# DSP_ICFG register map
Vendor: Texas Instruments
Peripheral module from a debugger description file (folder xwr16xx).
Registers are 32-bit, read-write, no defined reset value unless marked. A register's access mark holds for its fields unless they carry their own. Offsets are as the file gives them; lines under a group give offsets from that group; [hi:lo] are bit positions; {n}, {i} and the like mark numbered series; 'fields as' and 'values as' point back to an identical list; <NAME> marks a mode.

## DSP_ICFG
{0x800000+4i} EVTFLAG{i} (i=0..3) — Event flags
  [31:0] EF — Bitfield description is not available - (RO )
{0x800020+4i} EVTSET{i} (i=0..3) — Event set command register
  [31:0] ES — Event set command - (WO )
{0x800040+4i} EVTCLR{i} (i=0..3) — Event clear command register
  [31:0] EC — Event clear command - (WO )
{0x800080+4i} EVTMASK{i} (i=0..3) — Event mask register
  [31:0] EM — Event mask - (RW )
{0x8000A0+4i} MEVTFLAG{i} (i=0..3) — Masked event flags
  [31:0] MEVTFLAG — Masked event flags - (RO )
{0x8000C0+4i} EXPMASK{i} (i=0..3) — Exception mask register
  [31:0] XM — Exception mask - (RW )
{0x8000E0+4i} MEXPFLAG{i} (i=0..3) — Masked exception flags
  [31:0] MEXPFLAG — Masked exception flags - (RO )
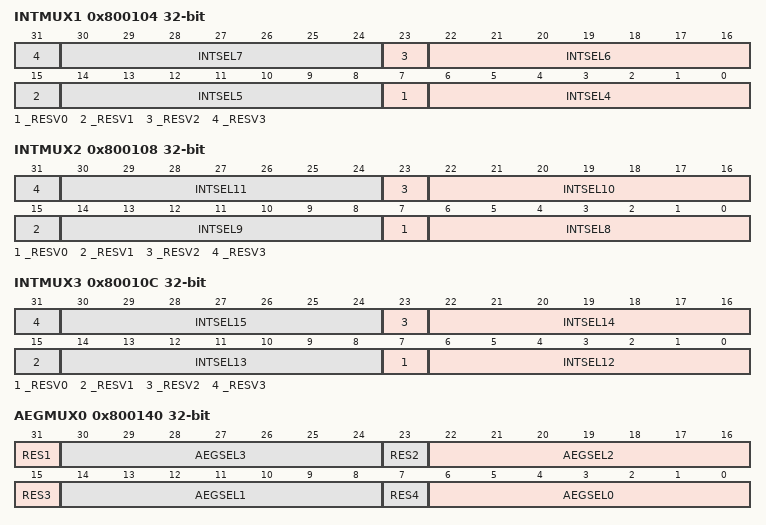
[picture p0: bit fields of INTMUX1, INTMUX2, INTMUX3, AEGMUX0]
0x800104 INTMUX1 — Interrupt Mux Register
  [8n+7] _RESV{n} (n=0..3) — Always read as 0. Writes have no affect. - (RW )
  [8n-26:8n-32] INTSEL{n} (n=4..7) — Interrupt selector {n} - (RW )
0x800108 INTMUX2 — Interrupt Mux Register
  [8n+7] _RESV{n} (n=0..3) — Always read as 0. Writes have no affect. - (RW )
  [8n-58:8n-64] INTSEL{n} (n=8..11) — Interrupt selector {n} - (RW )
0x80010C INTMUX3 — Interrupt Mux Register
  [8n+7] _RESV{n} (n=0..3) — Always read as 0. Writes have no affect. - (RW )
  [8n-90:8n-96] INTSEL{n} (n=12..15) — Interrupt selector {n} - (RW )
0x800140 AEGMUX0 access per field — AEG Event Mux Register
  [39-8n] RES{n} ro (n=1..4) — RESERVE FIELD
  [8n+6:8n] AEGSEL{n} rw (n=0..3) — AEG event selector {n} - (RW )
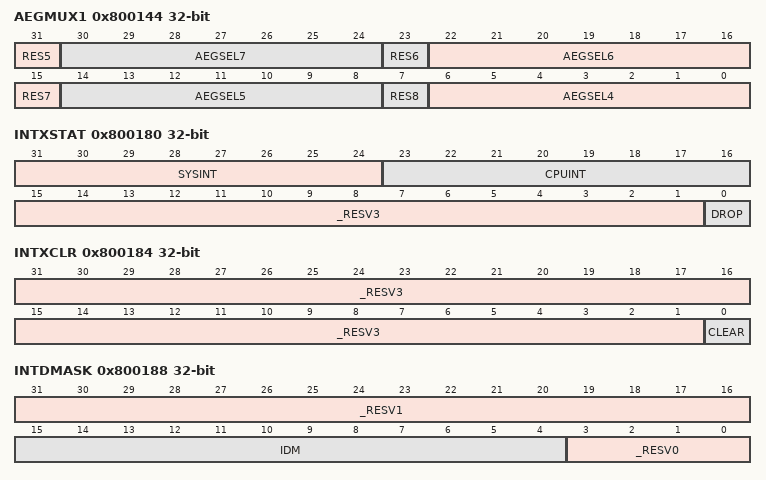
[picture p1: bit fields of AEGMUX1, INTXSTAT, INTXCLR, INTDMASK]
0x800144 AEGMUX1 access per field — AEG Event Mux Register
  [71-8n] RES{n} ro (n=5..8) — RESERVE FIELD
  [8n-26:8n-32] AEGSEL{n} rw (n=4..7) — AEG event selector {n} - (RW )
0x800180 INTXSTAT — Interrupt Exception Status Register
  [31:24] SYSINT — System event number - (RO )
  [23:16] CPUINT — CPU interrupt number - (RO )
  [15:1] _RESV3 — Always read as 0. Writes have no affect. - (RW )
  [0] DROP — Dropped event flag - (RO )
0x800184 INTXCLR — Interrupt Exception Clear Register
  [31:1] _RESV3 — Always read as 0. Writes have no affect. - (RW )
  [0] CLEAR — Clear interrupt exception status - (WO )
0x800188 INTDMASK — Dropped Interrupt Mask Register
  [31:16] _RESV1 — Always read as 0. Writes have no affect. - (RW )
  [15:4] IDM — Interrupt drop mask - (RW )
  [3:0] _RESV0 — Always read as 0. Writes have no affect. - (RW )
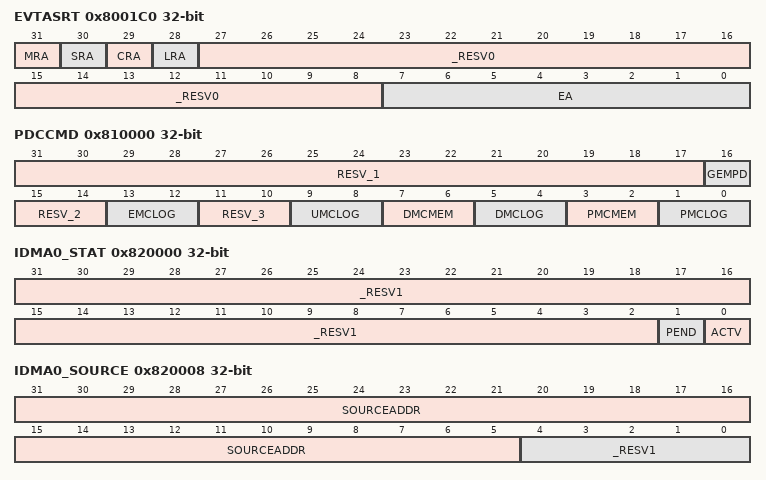
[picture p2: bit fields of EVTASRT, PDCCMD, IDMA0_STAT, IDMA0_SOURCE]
0x8001C0 EVTASRT — Event Assert Register
  [31] MRA — Maximal Reset Request Assert - (WO )
  [30] SRA — System Reset Request Assert - (WO )
  [29] CRA — Chip Reset Request Assert - (WO )
  [28] LRA — Local Reset Request Assert - (WO )
  [27:8] _RESV0 — Always read as 0. Writes have no affect. - (RW )
  [7:0] EA — Event Assert - (WO )
0x810000 PDCCMD — Register description is not available
  [31:17] RESV_1 — Always read as 0. Writes have no affect. - (RW )
  [16] GEMPD — Enable power-down during IDLE - (RW )
  [15:14] RESV_2 — Always read as 0. Writes have no affect. - (RW )
  [13:12] EMCLOG — EMC SRAM Sleep Mode - (RW )
  [11:10] RESV_3 — Always read as 0. Writes have no affect. - (RW )
  [9:8] UMCLOG — UMC SRAM Sleep Mode - (RW )
  [7:6] DMCMEM — DMC Logic Clock Gating - (RW )
  [5:4] DMCLOG — DMC SRAM Sleep Mode - (RW )
  [3:2] PMCMEM — PMC Logic Clock Gating - (RW )
  [1:0] PMCLOG — PMC SRAM Sleep Mode - (RW )
0x812000 MM_REVID — Register description is not available
  [31:0] MM_REVID — Bitfield description is not available - (RW )
0x820000 IDMA0_STAT — IDMA Channel 0 Status
  [31:2] _RESV1 — Always read as 0. Writes have no affect. - (RW )
  [1] PEND — Command pending - (RO )
  [0] ACTV — Command active - (RO )
0x820004 IDMA0_MASK — IDMA Channel 0 Register Mask
  [31:0] MASK — Register mask - (RW )
0x820008 IDMA0_SOURCE — IDMA Channel 0 Source Address
  [31:5] SOURCEADDR — Source address - (RW )
  [4:0] _RESV1 — Always read as 0. Writes have no affect. - (RW )
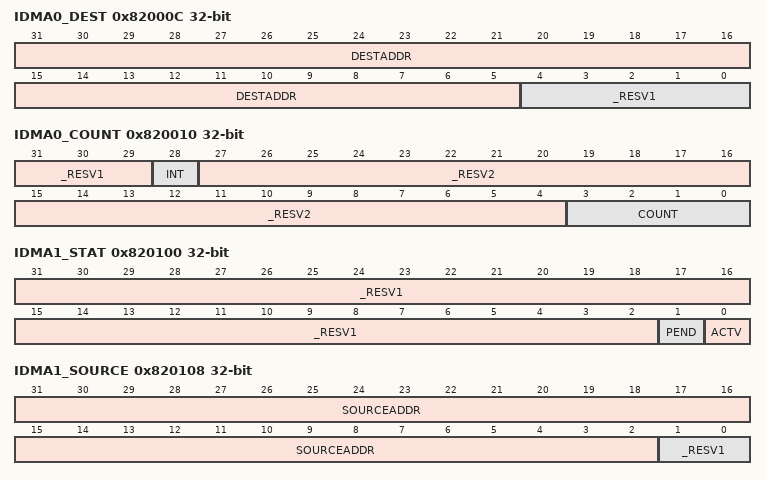
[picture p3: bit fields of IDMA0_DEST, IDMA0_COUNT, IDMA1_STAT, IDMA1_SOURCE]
0x82000C IDMA0_DEST — IDMA Channel 0 Destination Address
  [31:5] DESTADDR — Destination address - (RW )
  [4:0] _RESV1 — Always read as 0. Writes have no affect. - (RW )
0x820010 IDMA0_COUNT — IDMA Channel 0 Count
  [31:29] _RESV1 — Always read as 0. Writes have no affect. - (RW )
  [28] INT — Interrupt enable - (RW )
  [27:4] _RESV2 — Always read as 0. Writes have no affect. - (RW )
  [3:0] COUNT — Transfer frame count - (RW )
0x820100 IDMA1_STAT — Register description is not available
  fields as IDMA0_STAT
0x820108 IDMA1_SOURCE — Register description is not available
  [31:2] SOURCEADDR — Source address - (RW )
  [1:0] _RESV1 — Always read as 0. Writes have no affect. - (RW )
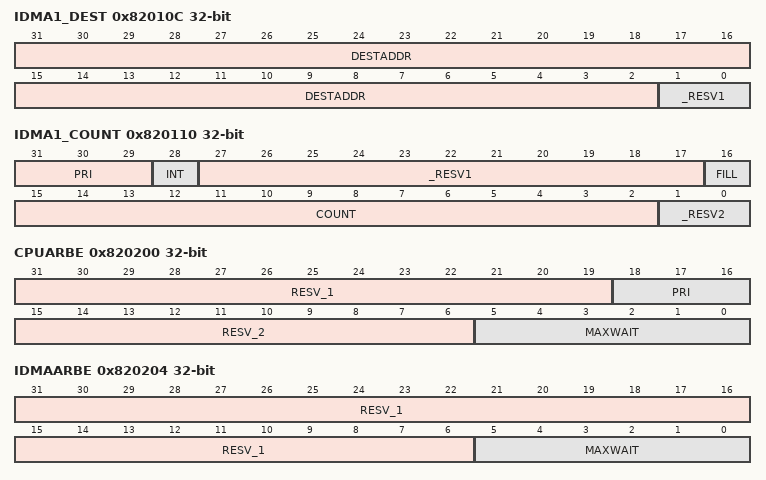
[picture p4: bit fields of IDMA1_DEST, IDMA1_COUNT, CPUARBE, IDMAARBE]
0x82010C IDMA1_DEST — Register description is not available
  [31:2] DESTADDR — Destination address - (RW )
  [1:0] _RESV1 — Always read as 0. Writes have no affect. - (RW )
0x820110 IDMA1_COUNT — Register description is not available
  [31:29] PRI — Priority - (RW )
  [28] INT — Interrupt enable - (RW )
  [27:17] _RESV1 — Always read as 0. Writes have no affect. - (RW )
  [16] FILL — Fill/Copy Mode Select - (RW )
  [15:2] COUNT — Transfer word count - (RW )
  [1:0] _RESV2 — Always read as 0. Writes have no affect. - (RW )
0x820200 CPUARBE — Register description is not available
  [31:19] RESV_1 — Always read as 0. Writes have no affect. - (RW )
  [18:16] PRI — Priority - (RW )
  [15:6] RESV_2 — Always read as 0. Writes have no affect. - (RW )
  [5:0] MAXWAIT — Max wait count - (RW )
0x820204 IDMAARBE — Register description is not available
  [31:6] RESV_1 — Always read as 0. Writes have no affect. - (RW )
  [5:0] MAXWAIT — Max wait count - (RW )
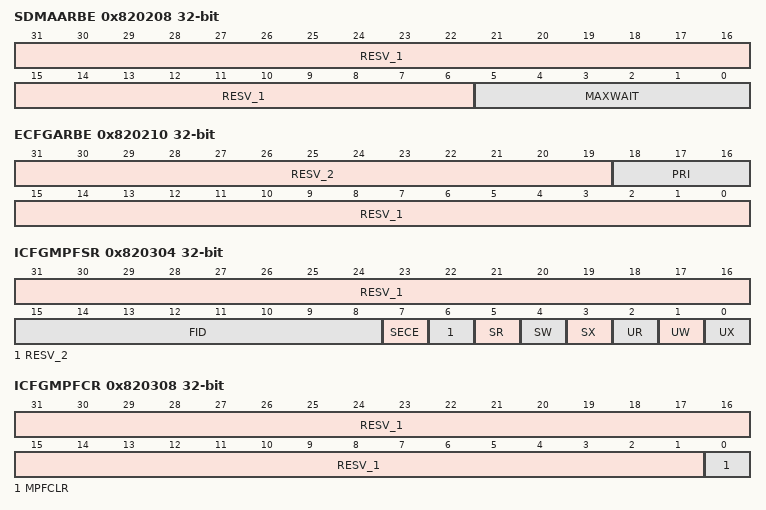
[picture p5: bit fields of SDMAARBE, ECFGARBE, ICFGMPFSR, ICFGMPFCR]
0x820208 SDMAARBE — Register description is not available
  fields as IDMAARBE
0x820210 ECFGARBE — Register description is not available
  [31:19] RESV_2 — Always read as 0. Writes have no affect. - (RW )
  [18:16] PRI — Priority - (RW )
  [15:0] RESV_1 — Always read as 0. Writes have no affect. - (RW )
0x820300 ICFGMPFAR — Register description is not available
  [31:0] ADDR — Bitfield description is not available - (RO )
0x820304 ICFGMPFSR — Register description is not available
  [31:16] RESV_1 — Always read as 0. Writes have no affect. - (RW )
  [15:8] FID — PrivID of faulting requestor - (RO )
  [7] SECE — Security Error - (RO )
  [6] RESV_2 — Always read as 0. Writes have no affect. - (RW )
  [5] SR — Fault due to Supervisor Read - (RO )
  [4] SW — Fault due to Supervisor Write - (RO )
  [3] SX — Fault due to Supervisor Execute - (RO )
  [2] UR — Fault due to User Read - (RO )
  [1] UW — Fault due to User Write - (RO )
  [0] UX — Fault due to User Execute - (RO )
0x820308 ICFGMPFCR — Register description is not available
  [31:1] RESV_1 — Always read as 0. Writes have no affect. - (RW )
  [0] MPFCLR — Bitfield description is not available - (WO )
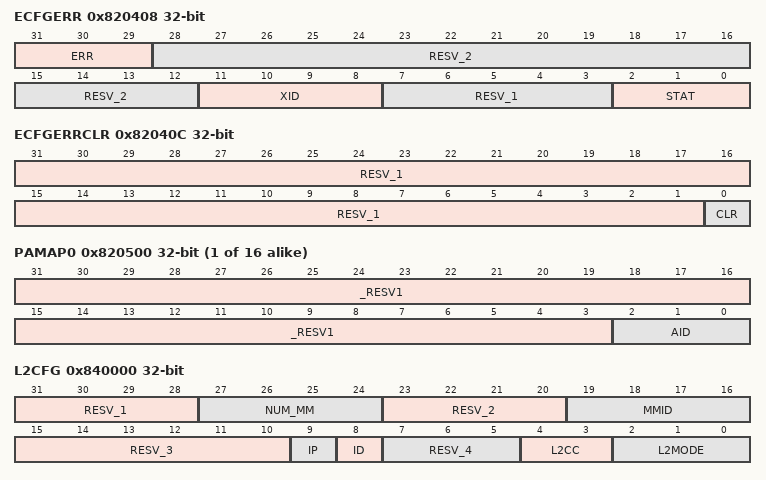
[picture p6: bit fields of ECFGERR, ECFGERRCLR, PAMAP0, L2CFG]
0x820408 ECFGERR — Register description is not available
  [31:29] ERR — Error - (RO )
  [28:12] RESV_2 — Always read as 0. Writes have no affect. - (RW )
  [11:8] XID — XID - (RO )
  [7:3] RESV_1 — Always read as 0. Writes have no affect. - (RW )
  [2:0] STAT — Status - (RO )
0x82040C ECFGERRCLR — Register description is not available
  [31:1] RESV_1 — Always read as 0. Writes have no affect. - (RW )
  [0] CLR — Error clear - (RO )
{0x820500+4i} PAMAP{i} (i=0..15) — PAMAP register
  [31:3] _RESV1 — Always read as 0. Writes have no affect. - (RW )
  [2:0] AID — AID - (RW )
0x840000 L2CFG — Register description is not available
  [31:28] RESV_1 — Always read as 0. Writes have no affect. - (RW )
  [27:24] NUM_MM — Bitfield description is not available - (RO )
  [23:20] RESV_2 — Always read as 0. Writes have no affect. - (RW )
  [19:16] MMID — Bitfield description is not available - (RO )
  [15:10] RESV_3 — Always read as 0. Writes have no affect. - (RW )
  [9] IP — Bitfield description is not available - (RW )
  [8] ID — Bitfield description is not available - (RW )
  [7:5] RESV_4 — Always read as 0. Writes have no affect. - (RW )
  [4:3] L2CC — Bitfield description is not available - (RW )
  [2:0] L2MODE — Bitfield description is not available - (RW )
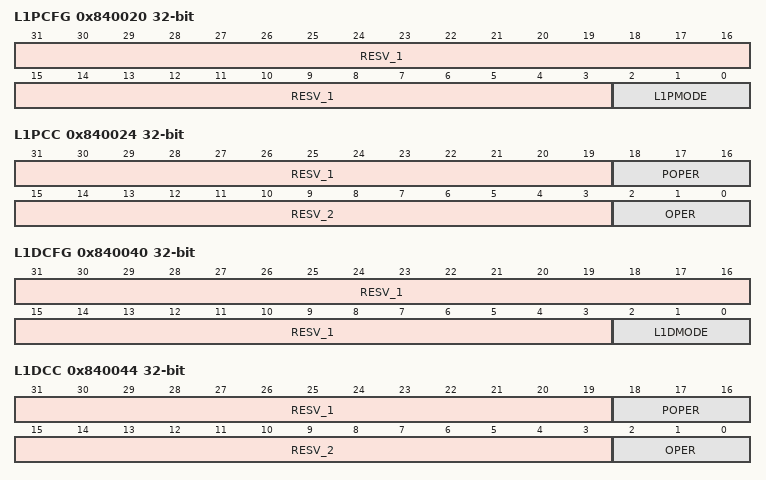
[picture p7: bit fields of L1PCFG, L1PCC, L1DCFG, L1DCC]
0x840020 L1PCFG — Register description is not available
  [31:3] RESV_1 — Always read as 0. Writes have no affect. - (RW )
  [2:0] L1PMODE — Bitfield description is not available - (RW )
0x840024 L1PCC — Register description is not available
  [31:19] RESV_1 — Always read as 0. Writes have no affect. - (RW )
  [18:16] POPER — Bitfield description is not available - (RO )
  [15:3] RESV_2 — Always read as 0. Writes have no affect. - (RW )
  [2:0] OPER — Bitfield description is not available - (RW )
0x840040 L1DCFG — Register description is not available
  [31:3] RESV_1 — Always read as 0. Writes have no affect. - (RW )
  [2:0] L1DMODE — Bitfield description is not available - (RW )
0x840044 L1DCC — Register description is not available
  fields as L1PCC
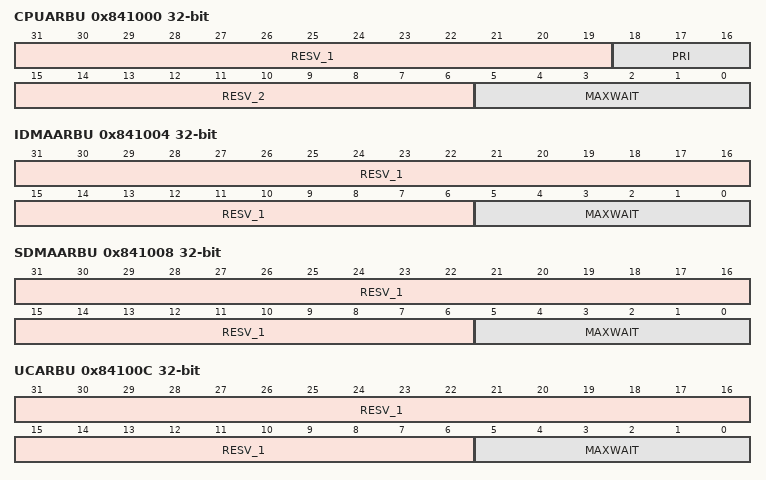
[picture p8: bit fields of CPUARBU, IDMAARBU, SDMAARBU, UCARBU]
0x841000 CPUARBU — Register description is not available
  fields as CPUARBE
0x841004 IDMAARBU — Register description is not available
  fields as IDMAARBE
0x841008 SDMAARBU — Register description is not available
  fields as IDMAARBE
0x84100C UCARBU — Register description is not available
  fields as IDMAARBE
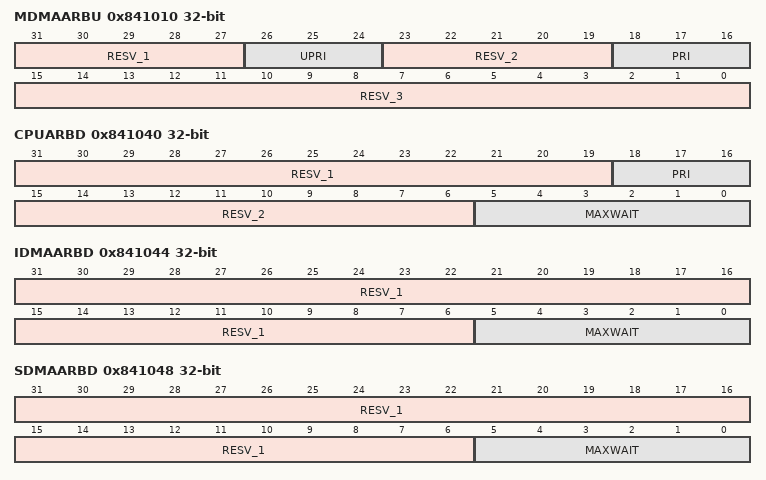
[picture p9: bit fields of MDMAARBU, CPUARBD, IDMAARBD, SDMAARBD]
0x841010 MDMAARBU — Register description is not available
  [31:27] RESV_1 — Always read as 0. Writes have no affect. - (RW )
  [26:24] UPRI — Elevated priority - (RW )
  [23:19] RESV_2 — Always read as 0. Writes have no affect. - (RW )
  [18:16] PRI — Default priority - (RW )
  [15:0] RESV_3 — Always read as 0. Writes have no affect. - (RW )
0x841040 CPUARBD — Register description is not available
  fields as CPUARBE
0x841044 IDMAARBD — Register description is not available
  fields as IDMAARBE
0x841048 SDMAARBD — Register description is not available
  fields as IDMAARBE
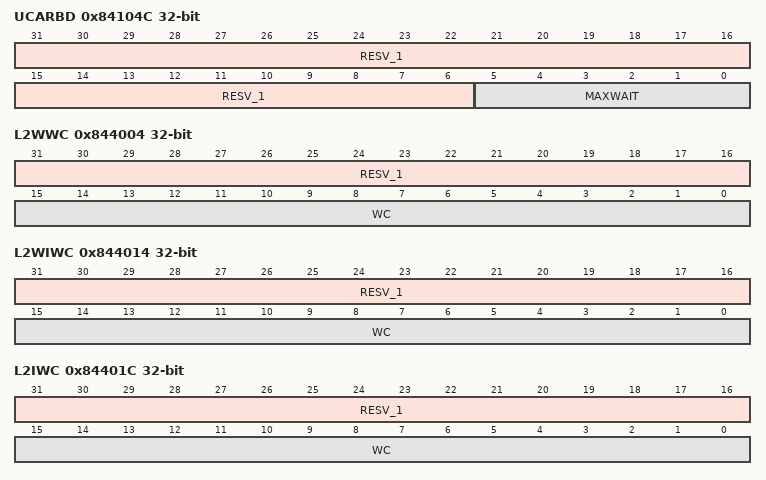
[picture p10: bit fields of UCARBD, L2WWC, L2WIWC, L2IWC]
0x84104C UCARBD — Register description is not available
  fields as IDMAARBE
0x844000 L2WBAR — Register description is not available
  [31:0] ADDR — Write only address register. - (WO )
0x844004 L2WWC — Register description is not available
  [31:16] RESV_1 — Always read as 0. Writes have no affect. - (RW )
  [15:0] WC — Bitfield description is not available - (RW )
0x844010 L2WIBAR — Register description is not available
  [31:0] ADDR — Write only address register. - (WO )
0x844014 L2WIWC — Register description is not available
  fields as L2WWC
0x844018 L2IBAR — Register description is not available
  [31:0] ADDR — Write only address register. - (WO )
0x84401C L2IWC — Register description is not available
  fields as L2WWC
0x844020 L1PIBAR — Register description is not available
  [31:0] ADDR — Write only address register. - (WO )
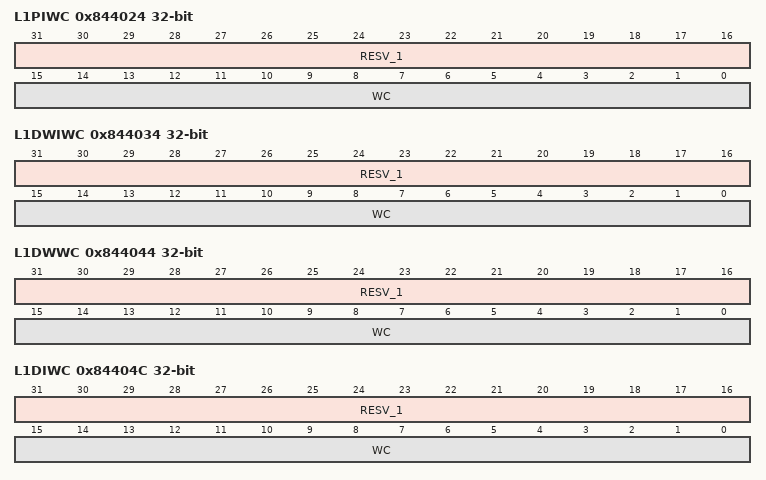
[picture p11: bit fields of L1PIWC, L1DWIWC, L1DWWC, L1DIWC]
0x844024 L1PIWC — Register description is not available
  fields as L2WWC
0x844030 L1DWIBAR — Register description is not available
  [31:0] ADDR — Write only address register - (WO )
0x844034 L1DWIWC — Register description is not available
  fields as L2WWC
0x844040 L1DWBAR — Register description is not available
  [31:0] ADDR — Write only address register - (WO )
0x844044 L1DWWC — Register description is not available
  fields as L2WWC
0x844048 L1DIBAR — Register description is not available
  [31:0] ADDR — Write only address register - (WO )
0x84404C L1DIWC — Register description is not available
  fields as L2WWC
0x845000 L2WB — Register description is not available
  [31:0] C — Bitfield description is not available - (RW )
0x845004 L2WBINV — Register description is not available
  [31:0] C — Bitfield description is not available - (RW )
0x845008 L2INV — Register description is not available
  [31:0] I — Bitfield description is not available - (RW )
0x845028 L1PINV — Register description is not available
  [31:0] I — Bitfield description is not available - (RW )
0x845040 L1DWB — Register description is not available
  [31:0] C — Bitfield description is not available - (RW )
0x845044 L1DWBINV — Register description is not available
  [31:0] C — Bitfield description is not available - (RW )
0x845048 L1DINV — Register description is not available
  [31:0] I — Bitfield description is not available - (RW )
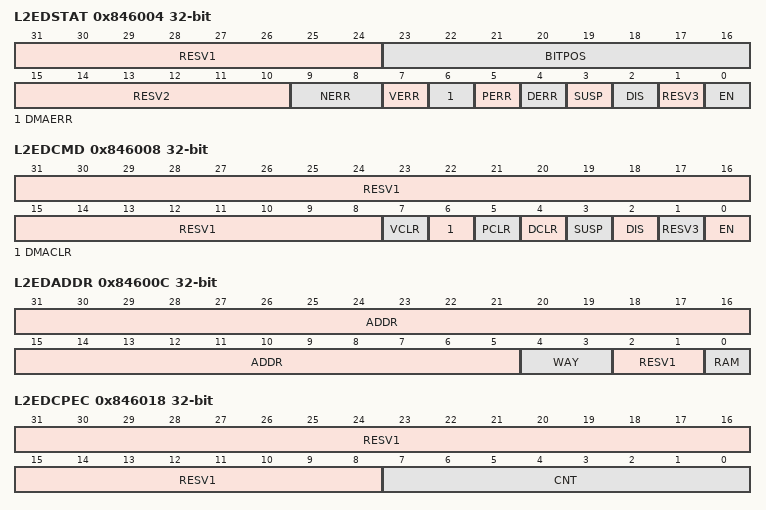
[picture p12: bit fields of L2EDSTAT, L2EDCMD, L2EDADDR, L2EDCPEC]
0x846004 L2EDSTAT — L2 EDC Status register
  [31:24] RESV1 — Always read as 0. Writes have no affect. - (RW )
  [23:16] BITPOS — Bit position of Error - (RO )
  [15:10] RESV2 — Always read as 0. Writes have no affect. - (RW )
  [9:8] NERR — Non correctable Error - (RO )
  [7] VERR — Victim EDC Error - (RO )
  [6] DMAERR — DMA EDC Error - (RO )
  [5] PERR — PMC Data EDC Error - (RO )
  [4] DERR — DMC Data EDC Error - (RO )
  [3] SUSP — EDC Suspend - (RO )
  [2] DIS — EDC Disable - (RO )
  [1] RESV3 — Always read as 0. Writes have no affect. - (RW )
  [0] EN — EDC Enable - (RO )
0x846008 L2EDCMD — L2 EDC Command register
  [31:8] RESV1 — Always read as 0. Writes have no affect. - (RW )
  [7] VCLR — Victim EDC Error - (WO )
  [6] DMACLR — DMA EDC Error - (WO )
  [5] PCLR — PMC Data EDC Error - (WO )
  [4] DCLR — DMC Data EDC Error - (WO )
  [3] SUSP — EDC Suspend - (WO )
  [2] DIS — EDC Disable - (WO )
  [1] RESV3 — Always read as 0. Writes have no affect. - (RW )
  [0] EN — EDC Enable - (WO )
0x84600C L2EDADDR — L2 EDC error address
  [31:5] ADDR — L2 Error detection address - (RO )
  [4:3] WAY — Addr way - (RO )
  [2:1] RESV1 — Always read as 0. Writes have no affect. - (RW )
  [0] RAM — Addr is sram - (RO )
0x846018 L2EDCPEC — L2 EDC correctable error count
  [31:8] RESV1 — Always read as 0. Writes have no affect. - (RW )
  [7:0] CNT — count - (RO )
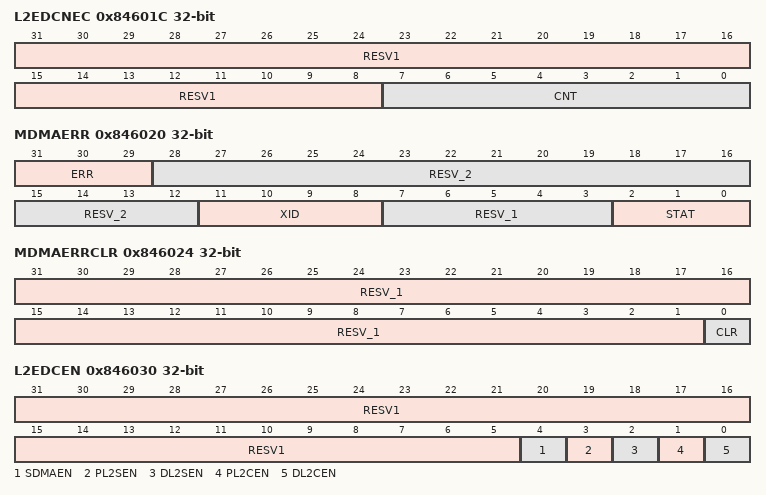
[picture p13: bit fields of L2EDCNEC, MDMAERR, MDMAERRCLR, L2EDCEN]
0x84601C L2EDCNEC — L2 EDC noncorrectable error count
  fields as L2EDCPEC
0x846020 MDMAERR — Register description is not available
  fields as ECFGERR
0x846024 MDMAERRCLR — Register description is not available
  fields as ECFGERRCLR
0x846030 L2EDCEN — L2 EDC enable register
  [31:5] RESV1 — Always read as 0. Writes have no affect. - (RW )
  [4] SDMAEN — Enable edc on sdma reads to l2 sram - (WO )
  [3] PL2SEN — Enable edc on pmc hits to l2 sram - (WO )
  [2] DL2SEN — Enable edc on dmc hits to l2 sram - (WO )
  [1] PL2CEN — Enable edc on pmc hits to l2 cache - (WO )
  [0] DL2CEN — Enable edc on dmc hits to l2 cache - (WO )
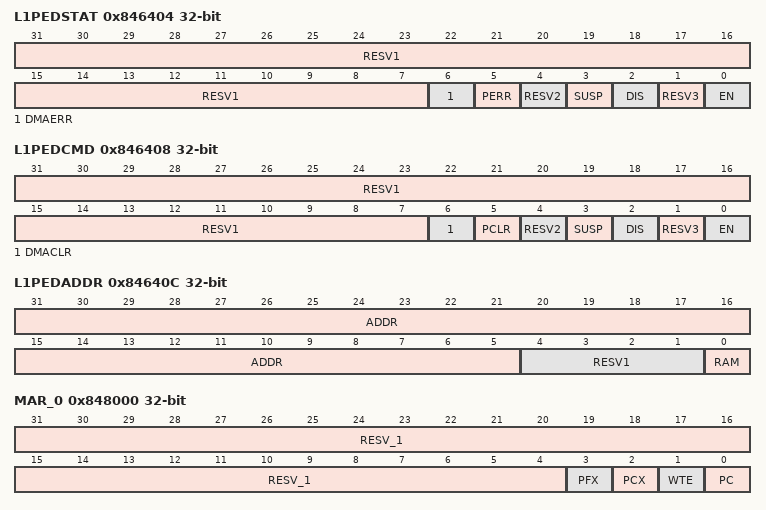
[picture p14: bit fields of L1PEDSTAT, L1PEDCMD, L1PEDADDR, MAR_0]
0x846404 L1PEDSTAT — L1P EDC Status register
  [31:7] RESV1 — Always read as 0. Writes have no affect. - (RW )
  [6] DMAERR — DMA Error - (RO )
  [5] PERR — Parity Error - (RO )
  [4] RESV2 — Always read as 0. Writes have no affect. - (RW )
  [3] SUSP — EDC Suspend - (RO )
  [2] DIS — EDC Disable - (RO )
  [1] RESV3 — Always read as 0. Writes have no affect. - (RW )
  [0] EN — EDC Enable - (RO )
0x846408 L1PEDCMD — L1P EDC Command register
  [31:7] RESV1 — Always read as 0. Writes have no affect. - (RW )
  [6] DMACLR — Clear DMA Error - (WO )
  [5] PCLR — Clear Parity Error - (WO )
  [4] RESV2 — Always read as 0. Writes have no affect. - (RW )
  [3] SUSP — EDC Suspend - (WO )
  [2] DIS — EDC Disable - (WO )
  [1] RESV3 — Always read as 0. Writes have no affect. - (RW )
  [0] EN — EDC Enable - (WO )
0x84640C L1PEDADDR — L1P EDC error address
  [31:5] ADDR — L1P Error detection address - (RO )
  [4:1] RESV1 — Always read as 0. Writes have no affect. - (RW )
  [0] RAM — Addr is sram - (RO )
0x848000 MAR_0 — MAR register
  [31:4] RESV_1 — Always read as 0. Writes have no affect. - (RW )
  [3] PFX — Hard coded to 0 - (RO )
  [2] PCX — Hard coded to 0 - (RO )
  [1] WTE — Hard coded to 0 - (RO )
  [0] PC — Hard coded to 1 - (RO )
{0x848000+4i} MAR_{i} (i=1..11) — MAR register
  [31:4] RESV_1 — Always read as 0. Writes have no affect. - (RW )
  [3] PFX — Hard coded to 0 - (RO )
  [2] PCX — Hard coded to 0 - (RO )
  [1] WTE — Hard coded to 0 - (RO )
  [0] PC — Hard coded to 0 - (RO )
{0x848000+4i} MAR_{i} (i=12..15) — MAR register
  [31:4] RESV_1 — Always read as 0. Writes have no affect. - (RW )
  [3] PFX — Bitfield description is not available - (RW )
  [2] PCX — Bitfield description is not available - (RW )
  [1] WTE — Bitfield description is not available - (RW )
  [0] PC — Bitfield description is not available - (RO )
{0x848000+4i} MAR_{i} (i=16..255) — MAR register
  [31:4] RESV_1 — Always read as 0. Writes have no affect. - (RW )
  [3] PFX — Bitfield description is not available - (RW )
  [2] PCX — Bitfield description is not available - (RW )
  [1] WTE — Bitfield description is not available - (RW )
  [0] PC — Bitfield description is not available - (RW )
0x84A000 L2MPFAR — Register description is not available
  [31:0] ADDR — Bitfield description is not available - (RO )
0x84A004 L2MPFSR — Register description is not available
  [31:16] RESV_1 — Always read as 0. Writes have no affect. - (RW )
  [15:9] FID — PrivID of faulting requestor - (RO )
  [8] LOCAL — Fault due to local CPU access - (RO )
  [7] NS — Fault due to non-secure code - (RO )
  [6] RESV_2 — Always read as 0. Writes have no affect. - (RW )
  [5] SR — Fault due to Supervisor Read - (RO )
  [4] SW — Fault due to Supervisor Write - (RO )
  [3] SX — Fault due to Supervisor Execute - (RO )
  [2] UR — Fault due to User Read - (RO )
  [1] UW — Fault due to User Write - (RO )
  [0] UX — Fault due to User Execute - (RO )
0x84A008 L2MPFCR — Register description is not available
  fields as ICFGMPFCR
{0x84A200+4i} L2MPPA{i} (i=0..31) — L2 Memory Protection Page Attribute register
  [31:16] RESV_1 — Always read as 0. Writes have no affect. - (RW )
  [n+10] AID{n} (n=0..5) — Allow ID {n} to access page - (RW )
  [9] AIDX — Allow IDs > 5 to access page - (RW )
  [8] LOCAL — Allow CPU to access page - (RW )
  [7] NS — Non-secure (Secure devices only) - (RW )
  [6] EMU — Emulatable (Secure devices only) - (RW )
  [5] SR — Supervisor Read Access - (RW )
  [4] SW — Supervisor Write Access - (RW )
  [3] SX — Supervisor Execute Access - (RW )
  [2] UR — User Read Access - (RW )
  [1] UW — User Write Access - (RW )
  [0] UX — User Execute Access - (RW )
0x84A400 L1PMPFAR — Register description is not available
  [31:0] ADDR — Bitfield description is not available - (RO )
0x84A404 L1PMPFSR — Register description is not available
  fields as L2MPFSR
0x84A408 L1PMPFCR — Register description is not available
  fields as ICFGMPFCR
{0x84A600+4i} L1PMPPA{i} (i=16..31) — L1P Memory Protection Page Attribute register
  fields as L2MPPA0
0x84AC00 L1DMPFAR — Register description is not available
  [31:0] ADDR — Bitfield description is not available - (RO )
0x84AC04 L1DMPFSR — Register description is not available
  fields as L2MPFSR
0x84AC08 L1DMPFCR — Register description is not available
  fields as ICFGMPFCR
{0x84AD00+4i} MPLK{i} (i=0..3) — MPLK register
  [31:0] MPLK — Bitfield description is not available - (WO )
0x84AD10 MPLKCMD — Register description is not available
  [31:3] RESV_1 — Always read as 0. Writes have no affect. - (RW )
  [2] KEYR — Bitfield description is not available - (WO )
  [1] LOCK — Bitfield description is not available - (WO )
  [0] UNLOCK — Bitfield description is not available - (WO )
0x84AD14 MPLKSTAT — Register description is not available
  [31:2] RESV_1 — Always read as 0. Writes have no affect. - (RW )
  [1] NSL — Bitfield description is not available - (RO )
  [0] LK — Bitfield description is not available - (RO )
{0x84AE00+4i} L1DMPPA{i} (i=16..31) — L1D Memory Protection Page Attribute register
  fields as L2MPPA0
